AUTOSAR XML (schema 4-2-1)
standard types defined: uint8
package /DataTypes
  range DC_uint8: phys 0..255, raw 0..255
  base type Base_uint8: category=FIXED_LENGTH, base-type-size=8, base-type-encoding=2C, mem-alignment=0, native-declaration=unsigned char
package /SWCs
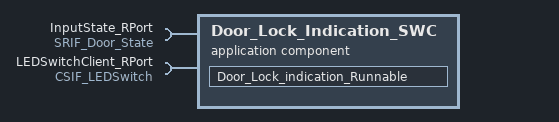
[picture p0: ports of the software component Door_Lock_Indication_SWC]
  application sw component type Door_Lock_Indication_SWC
    require port InputState_RPort: required-interface=SRIF_Door_State
    require port LEDSwitchClient_RPort: required-interface=CSIF_LEDSwitch
    behavior DoorLockInternalBehaviour
      data received event Door_Lock_Received_Event: start-on-event=Door_Lock_indication_Runnable, data=InputState_RPort.Door_State
      runnable Door_Lock_indication_Runnable: minimum-start-interval=1.0, symbol=Door_Lock_indication
        data-read-access:
          access Door_State: accessed-variable=InputState_RPort.Door_State
        sync call Call_LED_Switch: operation=LEDSwitchClient_RPort.LED_Switch
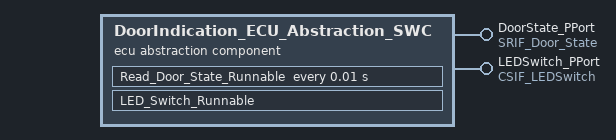
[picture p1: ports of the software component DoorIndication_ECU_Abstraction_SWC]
  ecu abstraction sw component type DoorIndication_ECU_Abstraction_SWC
    provide port DoorState_PPort: provided-interface=SRIF_Door_State
    provide port LEDSwitch_PPort: provided-interface=CSIF_LEDSwitch
    behavior ECU_Abs_internalBehaviour
      timing event read_DoorSensor_period_10ms: start-on-event=Read_Door_State_Runnable, period=0.01
      operation invoked event Led_Switch_invoke_Event: start-on-event=LED_Switch_Runnable, operation=LEDSwitch_PPort.LED_Switch
      runnable Read_Door_State_Runnable: minimum-start-interval=1.0, symbol=Read_Door_State
        data-write-access:
          access Door_State: accessed-variable=DoorState_PPort.Door_State
      runnable LED_Switch_Runnable: symbol=LED_Switch
package /Compositions
  composition sw component type RootSW_Composite
    component DoorLockIndicationAPPSWC: type=Door_Lock_Indication_SWC
    component DoorIndication_ECU_Abstraction_SWC: type=DoorIndication_ECU_Abstraction_SWC
    connect DoorIndication_ECU_Abstraction_SWC.DoorState_PPort -> DoorLockIndicationAPPSWC.InputState_RPort
    connect DoorIndication_ECU_Abstraction_SWC.LEDSwitch_PPort -> DoorLockIndicationAPPSWC.LEDSwitchClient_RPort
package /Interfaces
  sender receiver interface SRIF_Door_State
    data Door_State: type=uint8
  client server interface CSIF_LEDSwitch
    operation LED_Switch: possible-error=[E_OK, E_NOT_OK]
      arg LED_State: type=uint8, direction=IN
    error E_OK: error-code=0
    error E_NOT_OK: error-code=1
